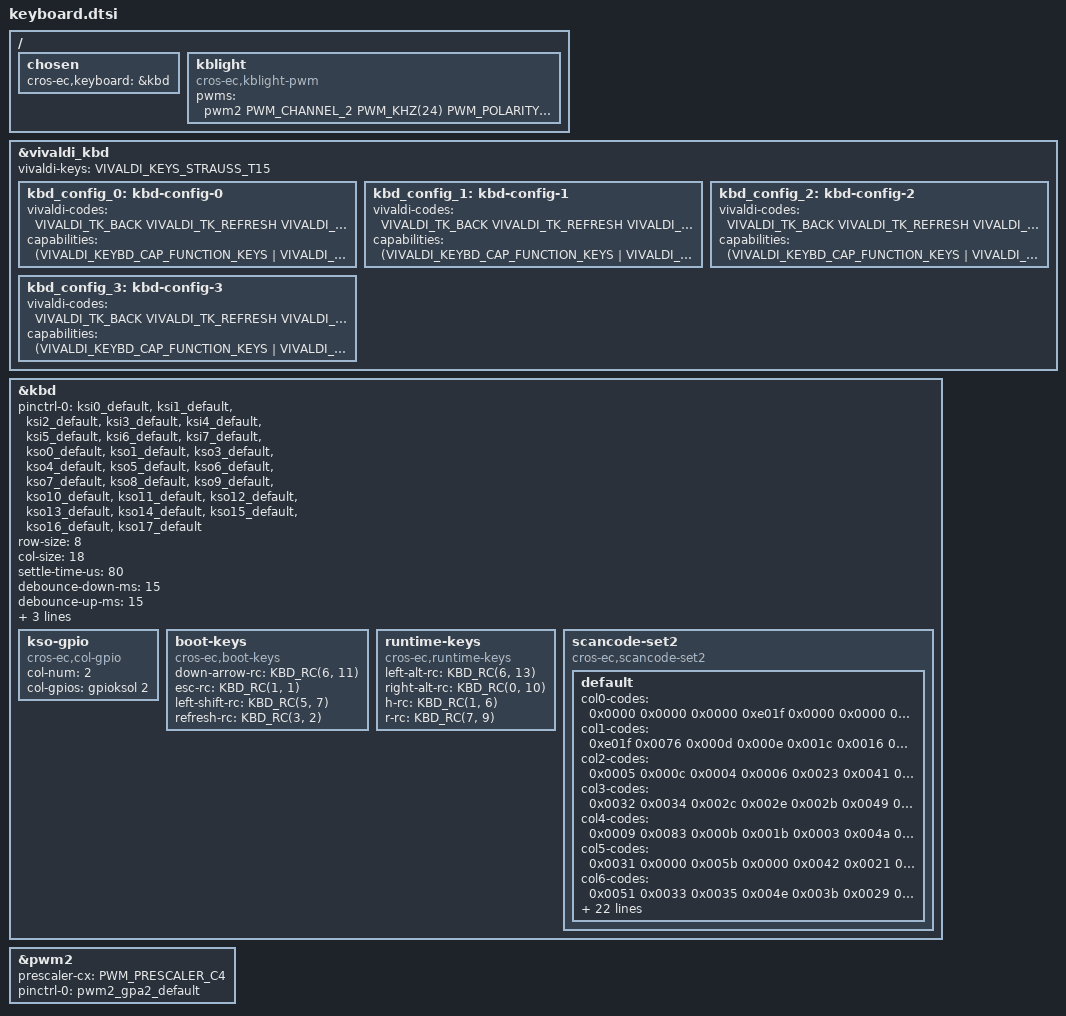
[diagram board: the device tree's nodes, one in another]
/* Copyright 2024 The ChromiumOS Authors
 * Use of this source code is governed by a BSD-style license that can be
 * found in the LICENSE file.
 */

/ {
	chosen {
		cros-ec,keyboard = &kbd;
		};

	kblight: kblight {
		compatible = "cros-ec,kblight-pwm";
		pwms = <&pwm2 PWM_CHANNEL_2 PWM_KHZ(24) PWM_POLARITY_NORMAL>;
	};
};

&vivaldi_kbd {
	vivaldi-keys = <VIVALDI_KEYS_STRAUSS_T15>;

	/* FW_KB_BL_NOT_PRESENT */
	kbd_config_0: kbd-config-0{
		vivaldi-codes = <
			VIVALDI_TK_BACK			/* T1 */
			VIVALDI_TK_REFRESH		/* T2 */
			VIVALDI_TK_FULLSCREEN		/* T3 */
			VIVALDI_TK_OVERVIEW		/* T4 */
			VIVALDI_TK_SNAPSHOT		/* T5 */
			VIVALDI_TK_BRIGHTNESS_DOWN	/* T6 */
			VIVALDI_TK_BRIGHTNESS_UP	/* T7 */
			VIVALDI_TK_DICTATE      	/* T8 */
			VIVALDI_TK_PLAY_PAUSE		/* T9 */
			VIVALDI_TK_MICMUTE		/* T10 */
			VIVALDI_TK_VOL_MUTE		/* T11 */
			VIVALDI_TK_VOL_DOWN		/* T12 */
			VIVALDI_TK_VOL_UP		/* T13 */
			>;
		capabilities = < (VIVALDI_KEYBD_CAP_FUNCTION_KEYS |
				VIVALDI_KEYBD_CAP_SCRNLOCK_KEY |
				VIVALDI_KEYBD_CAP_ASSISTANT_KEY) >;
	};

	/* FW_KB_BL_PRESENT */
	kbd_config_1: kbd-config-1{
		vivaldi-codes = <
			VIVALDI_TK_BACK			/* T1 */
			VIVALDI_TK_REFRESH		/* T2 */
			VIVALDI_TK_FULLSCREEN		/* T3 */
			VIVALDI_TK_OVERVIEW		/* T4 */
			VIVALDI_TK_SNAPSHOT		/* T5 */
			VIVALDI_TK_BRIGHTNESS_DOWN	/* T6 */
			VIVALDI_TK_BRIGHTNESS_UP	/* T7 */
			VIVALDI_TK_KBD_BKLIGHT_DOWN	/* T8 */
			VIVALDI_TK_KBD_BKLIGHT_UP	/* T9 */
			VIVALDI_TK_DICTATE		/* T10 */
			VIVALDI_TK_VOL_MUTE		/* T11 */
			VIVALDI_TK_VOL_DOWN		/* T12 */
			VIVALDI_TK_VOL_UP		/* T13 */
			>;
		capabilities = < (VIVALDI_KEYBD_CAP_FUNCTION_KEYS |
				VIVALDI_KEYBD_CAP_SCRNLOCK_KEY |
				VIVALDI_KEYBD_CAP_ASSISTANT_KEY) >;
	};

	/* FW_KB_NUMPAD_PRESENT & FW_KB_BL_NOT_PRESENT */
	kbd_config_2: kbd-config-2{
		vivaldi-codes = <
			VIVALDI_TK_BACK			/* T1 */
			VIVALDI_TK_REFRESH		/* T2 */
			VIVALDI_TK_FULLSCREEN		/* T3 */
			VIVALDI_TK_OVERVIEW		/* T4 */
			VIVALDI_TK_SNAPSHOT		/* T5 */
			VIVALDI_TK_BRIGHTNESS_DOWN	/* T6 */
			VIVALDI_TK_BRIGHTNESS_UP	/* T7 */
			VIVALDI_TK_DICTATE		/* T8 */
			VIVALDI_TK_DONOTDISTURB		/* T9 */
			VIVALDI_TK_ACCESSIBILITY	/* T10 */
			VIVALDI_TK_PLAY_PAUSE		/* T11 */
			VIVALDI_TK_MICMUTE		/* T12 */
			VIVALDI_TK_VOL_MUTE		/* T13 */
			VIVALDI_TK_VOL_DOWN		/* T14 */
			VIVALDI_TK_VOL_UP		/* T15 */
			>;
		capabilities = < (VIVALDI_KEYBD_CAP_FUNCTION_KEYS |
				VIVALDI_KEYBD_CAP_SCRNLOCK_KEY |
				VIVALDI_KEYBD_CAP_NUMERIC_KEYPAD |
				VIVALDI_KEYBD_CAP_ASSISTANT_KEY) >;
	};

	/* FW_KB_NUMPAD_PRESENT & FW_KB_BL_PRESENT */
	kbd_config_3: kbd-config-3{
		vivaldi-codes = <
			VIVALDI_TK_BACK			/* T1 */
			VIVALDI_TK_REFRESH		/* T2 */
			VIVALDI_TK_FULLSCREEN		/* T3 */
			VIVALDI_TK_OVERVIEW		/* T4 */
			VIVALDI_TK_SNAPSHOT		/* T5 */
			VIVALDI_TK_BRIGHTNESS_DOWN	/* T6 */
			VIVALDI_TK_BRIGHTNESS_UP	/* T7 */
			VIVALDI_TK_KBD_BKLIGHT_DOWN	/* T8 */
			VIVALDI_TK_KBD_BKLIGHT_UP	/* T9 */
			VIVALDI_TK_DICTATE		/* T10 */
			VIVALDI_TK_PLAY_PAUSE		/* T11 */
			VIVALDI_TK_MICMUTE		/* T12 */
			VIVALDI_TK_VOL_MUTE		/* T13 */
			VIVALDI_TK_VOL_DOWN		/* T14 */
			VIVALDI_TK_VOL_UP		/* T15 */
			>;
		capabilities = < (VIVALDI_KEYBD_CAP_FUNCTION_KEYS |
				VIVALDI_KEYBD_CAP_SCRNLOCK_KEY |
				VIVALDI_KEYBD_CAP_NUMERIC_KEYPAD |
				VIVALDI_KEYBD_CAP_ASSISTANT_KEY) >;
	};
};

&kbd {
	status = "okay";
	/* No KSO2 (it's inverted and implemented by GPIO) */
	pinctrl-0 = <
		&ksi0_default
		&ksi1_default
		&ksi2_default
		&ksi3_default
		&ksi4_default
		&ksi5_default
		&ksi6_default
		&ksi7_default
		&kso0_default
		&kso1_default
		&kso3_default
		&kso4_default
		&kso5_default
		&kso6_default
		&kso7_default
		&kso8_default
		&kso9_default
		&kso10_default
		&kso11_default
		&kso12_default
		&kso13_default
		&kso14_default
		&kso15_default
		&kso16_default
		&kso17_default
	>;

	pinctrl-names = "default";
	row-size = <8>;
	col-size = <18>;
	settle-time-us = <80>;
	debounce-down-ms = <15>;
	debounce-up-ms = <15>;
	actual-key-mask = <0x08 0xff 0xff 0xff 0xff 0xf5 0xff 0xa4
			   0xff 0xfe 0x55 0xff 0xca 0x40 0x0a 0x40
			   0xff 0xff>;
	kso-ignore-mask = <04>;

	kso-gpio {
		compatible = "cros-ec,col-gpio";
		col-num = <2>;
		col-gpios = <&gpioksol 2 GPIO_ACTIVE_HIGH>;
	};

	boot-keys {
		compatible = "cros-ec,boot-keys";
		down-arrow-rc = <KBD_RC(6, 11)>;
		esc-rc = <KBD_RC(1, 1)>;
		left-shift-rc = <KBD_RC(5, 7)>;
		refresh-rc = <KBD_RC(3, 2)>;
	};

	runtime-keys {
		compatible = "cros-ec,runtime-keys";
		left-alt-rc = <KBD_RC(6, 13)>;
		right-alt-rc = <KBD_RC(0, 10)>;
		h-rc = <KBD_RC(1, 6)>;
		r-rc = <KBD_RC(7, 9)>;
	};

	scancode-set2 {
		compatible = "cros-ec,scancode-set2";

		default {
			col0-codes  = <0x0000 0x0000 0x0000 0xe01f 0x0000 0x0000 0x0000 0x0000>;
			col1-codes  = <0xe01f 0x0076 0x000d 0x000e 0x001c 0x0016 0x001a 0x003c>;
			col2-codes  = <0x0005 0x000c 0x0004 0x0006 0x0023 0x0041 0x0026 0x0043>;
			col3-codes  = <0x0032 0x0034 0x002c 0x002e 0x002b 0x0049 0x0025 0x0044>;
			col4-codes  = <0x0009 0x0083 0x000b 0x001b 0x0003 0x004a 0x001e 0x004d>;
			col5-codes  = <0x0031 0x0000 0x005b 0x0000 0x0042 0x0021 0x003e 0x0015>;
			col6-codes  = <0x0051 0x0033 0x0035 0x004e 0x003b 0x0029 0x0045 0x001d>;
			col7-codes  = <0x0000 0x0000 0x0061 0x0000 0x0000 0x0012 0x0000 0x0059>;
			col8-codes  = <0x0055 0x0052 0x0054 0x0036 0x004c 0x0022 0x003d 0x0024>;
			col9-codes  = <0x0000 0x0001 0xe071 0x002f 0x004b 0x002a 0x0046 0x002d>;
			col10-codes = <0xe011 0x0000 0x006a 0x0000 0x0037 0x0000 0x005d 0x0000>;
			col11-codes = <0xe071 0x0066 0x000a 0x005d 0x005a 0x003a 0xe072 0xe075>;
			col12-codes = <0x0000 0x0064 0x0000 0x0067 0x0000 0x0000 0xe074 0xe06b>;
			col13-codes = <0x0000 0x0000 0x0000 0x0000 0x0000 0x0000 0x0011 0x0000>;
			col14-codes = <0x0000 0x0014 0x0000 0xe014 0x0000 0x0000 0x0000 0x0000>;
			col15-codes = <0x0000 0x0000 0x0000 0x0000 0x0000 0x0000 0x0027 0x0000>;
			col16-codes = <0xe04a 0x007c 0x007b 0x0074 0x0071 0x0073 0x006b 0x0070>;
			col17-codes = <0x006c 0x0075 0x007d 0x0079 0x007a 0x0072 0x0069 0xe05a>;
		};
	};
};

/* pwm for KB BL */
 &pwm2 {
	status = "okay";
	prescaler-cx = <PWM_PRESCALER_C4>;
	pinctrl-0 = <&pwm2_gpa2_default>;
	pinctrl-names = "default";
};
